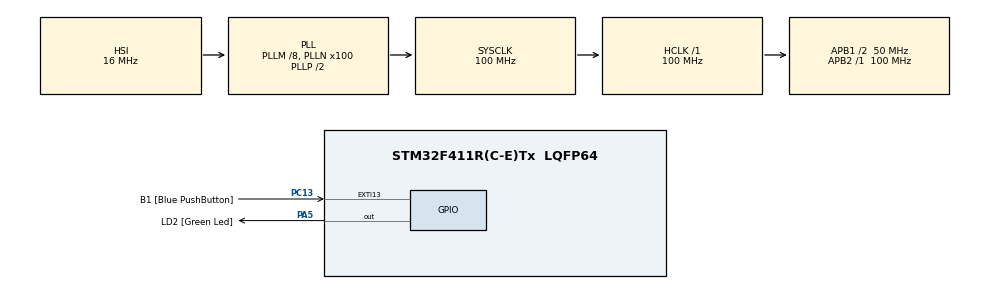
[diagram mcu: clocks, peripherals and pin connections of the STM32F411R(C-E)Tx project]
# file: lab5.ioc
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FREERTOS.INCLUDE_vTaskDelayUntil=1
FREERTOS.Mutexes01=myMutex01
FREERTOS.Tasks01=defaultTask,0,128,StartDefaultTask
Mcu.Family=STM32F4
Mcu.Name=STM32F411R(C-E)Tx
Mcu.Package=LQFP64
NVIC.PriorityGroup=NVIC_PRIORITYGROUP_4
PA13.GPIO_Label=TMS
PA13.Mode=Trace-Asynchronous_SW
PA13.Signal=SYS_JTMS-SWDIO
PA14.GPIO_Label=TCK
PA14.Mode=Trace-Asynchronous_SW
PA14.Signal=SYS_JTCK-SWCLK
PA2.GPIO_Label=USART_TX
PA2.Signal=USART2_TX
PA3.GPIO_Label=USART_RX
PA3.Signal=USART2_RX
PA5.GPIO_Label=LD2 [Green Led]
PA5.Signal=GPIO_Output
PB3.GPIO_Label=SWO
PB3.Mode=Trace-Asynchronous_SW
PB3.Signal=SYS_JTDO-SWO
PC13-ANTI_TAMP.GPIO_Label=B1 [Blue PushButton]
PC13-ANTI_TAMP.GPIO_ModeDefaultEXTI=GPIO_MODE_EVT_RISING
PC13-ANTI_TAMP.Signal=GPXTI13
PC14-OSC32_IN.Signal=RCC_OSC32_IN
PC15-OSC32_OUT.Signal=RCC_OSC32_OUT
PH0\ -\ OSC_IN.Signal=RCC_OSC_IN
PH1\ -\ OSC_OUT.Signal=RCC_OSC_OUT
ProjectManager.TargetToolchain=TrueSTUDIO
RCC.48MHZClocksFreq_Value=50000000
RCC.AHBFreq_Value=100000000
RCC.APB1CLKDivider=RCC_HCLK_DIV2
RCC.APB1Freq_Value=50000000
RCC.APB1TimFreq_Value=100000000
RCC.APB2Freq_Value=100000000
RCC.APB2TimFreq_Value=100000000
RCC.CortexFreq_Value=100000000
RCC.FLatency-AdvancedSettings=FLASH_LATENCY_2
RCC.HCLKFreq_Value=100000000
RCC.HSE_VALUE=8000000
RCC.HSI_VALUE=16000000
RCC.LSE_VALUE=32768
RCC.PLLM=8
RCC.PLLN=100
RCC.SYSCLKFreq_VALUE=100000000
RCC.SYSCLKSource=RCC_SYSCLKSOURCE_PLLCLK
RCC.VCOOutputFreq_Value=200000000
VP_FREERTOS_VS_ENABLE.Mode=Enabled
board=NUCLEO-F411RE

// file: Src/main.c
/**
  ******************************************************************************
  * File Name          : main.c
  * Description        : Main program body
  ******************************************************************************
  *
  * COPYRIGHT(c) 2016 STMicroelectronics
  *
  * Redistribution and use in source and binary forms, with or without modification,
  * are permitted provided that the following conditions are met:
  *   1. Redistributions of source code must retain the above copyright notice,
  *      this list of conditions and the following disclaimer.
  *   2. Redistributions in binary form must reproduce the above copyright notice,
  *      this list of conditions and the following disclaimer in the documentation
  *      and/or other materials provided with the distribution.
  *   3. Neither the name of STMicroelectronics nor the names of its contributors
  *      may be used to endorse or promote products derived from this software
  *      without specific prior written permission.
  *
  * THIS SOFTWARE IS PROVIDED BY THE COPYRIGHT HOLDERS AND CONTRIBUTORS "AS IS"
  * AND ANY EXPRESS OR IMPLIED WARRANTIES, INCLUDING, BUT NOT LIMITED TO, THE
  * IMPLIED WARRANTIES OF MERCHANTABILITY AND FITNESS FOR A PARTICULAR PURPOSE ARE
  * DISCLAIMED. IN NO EVENT SHALL THE COPYRIGHT HOLDER OR CONTRIBUTORS BE LIABLE
  * FOR ANY DIRECT, INDIRECT, INCIDENTAL, SPECIAL, EXEMPLARY, OR CONSEQUENTIAL
  * DAMAGES (INCLUDING, BUT NOT LIMITED TO, PROCUREMENT OF SUBSTITUTE GOODS OR
  * SERVICES; LOSS OF USE, DATA, OR PROFITS; OR BUSINESS INTERRUPTION) HOWEVER
  * CAUSED AND ON ANY THEORY OF LIABILITY, WHETHER IN CONTRACT, STRICT LIABILITY,
  * OR TORT (INCLUDING NEGLIGENCE OR OTHERWISE) ARISING IN ANY WAY OUT OF THE USE
  * OF THIS SOFTWARE, EVEN IF ADVISED OF THE POSSIBILITY OF SUCH DAMAGE.
  *
  ******************************************************************************
  */
#include "stm32f4xx_hal.h"
#include "cmsis_os.h"
#define STACK_SIZE 1000

osThreadId defaultTaskHandle;
osMutexId myMutex01Handle;
TaskHandle_t xHandleToBlink10Task = NULL;

/* USER CODE BEGIN PV */
/* Private variables ---------------------------------------------------------*/

/* USER CODE END PV */

void SystemClock_Config(void);
static void MX_GPIO_Init(void);
void StartDefaultTask(void const * argument);

/* USER CODE BEGIN PFP */
/* Private function prototypes -----------------------------------------------*/
void vTaskCodeBlink1( void * pvParameters );
void vTaskCodeBlink10( void * pvParameters );
void vTaskCodeCheckButton( void * pvParameters );
void vOtherFunction( void );

/* USER CODE END PFP */

int main(void)
{

  /* MCU Configuration----------------------------------------------------------*/

  /* Reset of all peripherals, Initializes the Flash interface and the Systick. */
  HAL_Init();

  /* Configure the system clock */
  SystemClock_Config();

  /* Initialize all configured peripherals */
  MX_GPIO_Init();

  /* Create the mutex(es) */
  /* definition and creation of myMutex01 */
  osMutexDef(myMutex01);
  myMutex01Handle = osMutexCreate(osMutex(myMutex01));

  /* Create the thread(s) */
  /* definition and creation of defaultTask */
  osThreadDef(defaultTask, StartDefaultTask, osPriorityNormal, 0, 128);
  defaultTaskHandle = osThreadCreate(osThread(defaultTask), NULL);
  vOtherFunction();

  /* Start scheduler */
  osKernelStart();

  /* We should never get here as control is now taken by the scheduler */

  /* Infinite loop */
  while (1)
  {

  }

}

/** System Clock Configuration
*/
void SystemClock_Config(void)
{

  RCC_OscInitTypeDef RCC_OscInitStruct;
  RCC_ClkInitTypeDef RCC_ClkInitStruct;

  __PWR_CLK_ENABLE();

  __HAL_PWR_VOLTAGESCALING_CONFIG(PWR_REGULATOR_VOLTAGE_SCALE1);

  RCC_OscInitStruct.OscillatorType = RCC_OSCILLATORTYPE_HSI;
  RCC_OscInitStruct.HSIState = RCC_HSI_ON;
  RCC_OscInitStruct.HSICalibrationValue = 16;
  RCC_OscInitStruct.PLL.PLLState = RCC_PLL_ON;
  RCC_OscInitStruct.PLL.PLLSource = RCC_PLLSOURCE_HSI;
  RCC_OscInitStruct.PLL.PLLM = 8;
  RCC_OscInitStruct.PLL.PLLN = 100;
  RCC_OscInitStruct.PLL.PLLP = RCC_PLLP_DIV2;
  RCC_OscInitStruct.PLL.PLLQ = 4;
  HAL_RCC_OscConfig(&RCC_OscInitStruct);

  RCC_ClkInitStruct.ClockType = RCC_CLOCKTYPE_SYSCLK|RCC_CLOCKTYPE_PCLK1;
  RCC_ClkInitStruct.SYSCLKSource = RCC_SYSCLKSOURCE_PLLCLK;
  RCC_ClkInitStruct.AHBCLKDivider = RCC_SYSCLK_DIV1;
  RCC_ClkInitStruct.APB1CLKDivider = RCC_HCLK_DIV2;
  RCC_ClkInitStruct.APB2CLKDivider = RCC_HCLK_DIV1;
  HAL_RCC_ClockConfig(&RCC_ClkInitStruct, FLASH_LATENCY_2);

  HAL_SYSTICK_Config(HAL_RCC_GetHCLKFreq()/1000);

  HAL_SYSTICK_CLKSourceConfig(SYSTICK_CLKSOURCE_HCLK);

  /* SysTick_IRQn interrupt configuration */
  HAL_NVIC_SetPriority(SysTick_IRQn, 15, 0);
}

/** Configure pins as
        * Analog
        * Input
        * Output
        * EVENT_OUT
        * EXTI
     PA2   ------> USART2_TX
     PA3   ------> USART2_RX
*/
void MX_GPIO_Init(void)
{

  GPIO_InitTypeDef GPIO_InitStruct;

  /* GPIO Ports Clock Enable */
  __GPIOC_CLK_ENABLE();
  __GPIOH_CLK_ENABLE();
  __GPIOA_CLK_ENABLE();
  __GPIOB_CLK_ENABLE();

  /*Configure GPIO pin : B1_Pin */
  GPIO_InitStruct.Pin = B1_Pin;
  GPIO_InitStruct.Mode = GPIO_MODE_EVT_RISING;
  GPIO_InitStruct.Pull = GPIO_NOPULL;
  HAL_GPIO_Init(B1_GPIO_Port, &GPIO_InitStruct);

  /*Configure GPIO pins : USART_TX_Pin USART_RX_Pin */
  GPIO_InitStruct.Pin = USART_TX_Pin|USART_RX_Pin;
  GPIO_InitStruct.Mode = GPIO_MODE_AF_PP;
  GPIO_InitStruct.Pull = GPIO_NOPULL;
  GPIO_InitStruct.Speed = GPIO_SPEED_HIGH;
  GPIO_InitStruct.Alternate = GPIO_AF7_USART2;
  HAL_GPIO_Init(GPIOA, &GPIO_InitStruct);

  /*Configure GPIO pin : LD2_Pin */
  GPIO_InitStruct.Pin = LD2_Pin;
  GPIO_InitStruct.Mode = GPIO_MODE_OUTPUT_PP;
  GPIO_InitStruct.Pull = GPIO_NOPULL;
  GPIO_InitStruct.Speed = GPIO_SPEED_LOW;
  HAL_GPIO_Init(LD2_GPIO_Port, &GPIO_InitStruct);

}

/* USER CODE BEGIN 4 */
void vTaskCodeBlink1( void * pvParameters )
{

	 TickType_t xLastWakeTime;
	 const TickType_t xFrequency = 1;

	     // Initialise the xLastWakeTime variable with the current time.
	     xLastWakeTime = xTaskGetTickCount();

  for( ;; )
  {
	  // Wait for the next cycle.
	  vTaskDelayUntil( &xLastWakeTime, xFrequency );
      /* Task code goes here. */
	  if( xSemaphoreTake( myMutex01Handle, ( TickType_t ) 10 ) == pdTRUE )
	  {
		  HAL_GPIO_TogglePin(LD2_GPIO_Port, LD2_Pin);
		  xSemaphoreGive( myMutex01Handle );
	  }
  }
}
void vTaskCodeBlink10( void * pvParameters )
{

	 TickType_t xLastWakeTime;
	 const TickType_t xFrequency = 5;

	     // Initialise the xLastWakeTime variable with the current time.
	     xLastWakeTime = xTaskGetTickCount();

  for( ;; )
  {
	  // Wait for the next cycle.
	  vTaskDelayUntil( &xLastWakeTime, xFrequency );
      /* Task code goes here. */
	  if( xSemaphoreTake( myMutex01Handle, ( TickType_t ) 10 ) == pdTRUE )
	  {
		  HAL_GPIO_TogglePin(LD2_GPIO_Port, LD2_Pin);
	  }
  }
}
void vTaskCodeCheckButton( void * pvParameters )
{
	static GPIO_TypeDef  GPIOStruct;
	static GPIO_TypeDef* GPIOx;
	GPIOx = &GPIOStruct;

	 TickType_t xLastWakeTime;
	 const TickType_t xFrequency = 5;

	     // Initialise the xLastWakeTime variable with the current time.
	     xLastWakeTime = xTaskGetTickCount();

  for( ;; )
  {
	  // Wait for the next cycle.
	  vTaskDelayUntil( &xLastWakeTime, xFrequency );
      /* Task code goes here. */
	  //HAL_GPIO_TogglePin(LD2_GPIO_Port, LD2_Pin);
	  if(HAL_GPIO_ReadPin(GPIOx, PC13) == 1)
		  vTaskResume(xHandleToBlink10Task);
  }
}

void vOtherFunction( void )
{
static unsigned char ucParameterToPass;
TaskHandle_t xHandle = NULL;
TaskHandle_t xHandle3 = NULL;

  /* Create the task, storing the handle.  Note that the passed parameter
  ucParameterToPass must exist for the lifetime of the task, so in this
  case is declared static.  If it was just an an automatic stack variable
  it might no longer exist, or at least have been corrupted, by the time
  the new task attempts to access it. */
volatile int i = 0;
i = xTaskCreate( vTaskCodeBlink1, "NAME1", STACK_SIZE, &ucParameterToPass, tskIDLE_PRIORITY +2,
               &xHandle );

i = xTaskCreate( vTaskCodeBlink10, "NAME2", STACK_SIZE, &ucParameterToPass, tskIDLE_PRIORITY +1,
               &xHandleToBlink10Task );
vTaskSuspend( xHandleToBlink10Task );

i = xTaskCreate( vTaskCodeCheckButton, "NAME3", STACK_SIZE, &ucParameterToPass, tskIDLE_PRIORITY +1,
               &xHandle3 );

  // Use the handle to raise the priority of the created task.
       //vTaskPrioritySet( xHandle, tskIDLE_PRIORITY + 1 );

 }

/* USER CODE END 4 */

/* StartDefaultTask function */
void StartDefaultTask(void const * argument)
{

  for(;;)
  {
    osDelay(1);
  }
}

/************************ (C) COPYRIGHT STMicroelectronics *****END OF FILE****/
